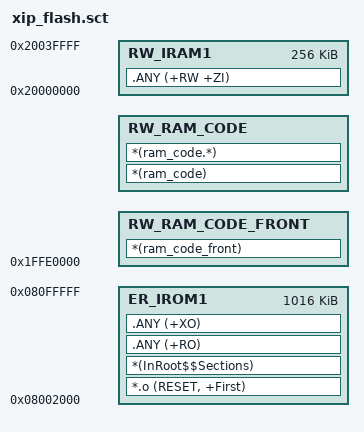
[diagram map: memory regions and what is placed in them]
; *************************************************************
; *** Scatter-Loading Description File generated by uVision ***
; *************************************************************

LR_IROM1 0x08002000 0x000FE000  {    ; load region size_region
  ER_IROM1 0x08002000 0x000FE000  {  ; load address = execution address
   *.o (RESET, +First)
   *(InRoot$$Sections)
   .ANY (+RO)
   .ANY (+XO)
  }
  RW_RAM_CODE_FRONT 0x1FFE0000  {
    *(ram_code_front)
  }
  RW_RAM_CODE +0 {
   *(ram_code)
   *(ram_code.*)
  }
  RW_IRAM1 0x20000000 0x00040000  {  ; RW data
   .ANY (+RW +ZI)
  }

  ScatterAssert((ImageLength(RW_RAM_CODE_FRONT)+ImageLength(RW_RAM_CODE)) <= 0x20000)
}

